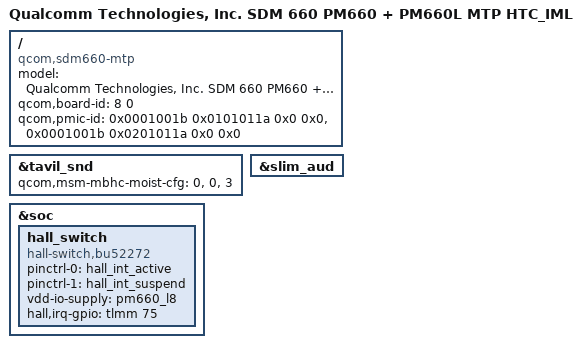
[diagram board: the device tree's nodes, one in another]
/* Copyright (c) 2016-2017, The Linux Foundation. All rights reserved.
 *
 * This program is free software; you can redistribute it and/or modify
 * it under the terms of the GNU General Public License version 2 and
 * only version 2 as published by the Free Software Foundation.
 *
 * This program is distributed in the hope that it will be useful,
 * but WITHOUT ANY WARRANTY; without even the implied warranty of
 * MERCHANTABILITY or FITNESS FOR A PARTICULAR PURPOSE.  See the
 * GNU General Public License for more details.
 */


/dts-v1/;

#include "sdm660-htc_iml.dtsi"
#include "sdm660-mtp-htc_iml.dtsi"
#include "sdm660-external-codec.dtsi"
#include "synaptics-dsx-i2c.dtsi"

/ {
	model = "Qualcomm Technologies, Inc. SDM 660 PM660 + PM660L MTP HTC_IML";
	compatible = "qcom,sdm660-mtp", "qcom,sdm660", "qcom,mtp";
	qcom,board-id = <8 0>;
	qcom,pmic-id = <0x0001001b 0x0101011a 0x0 0x0>,
			<0x0001001b 0x0201011a 0x0 0x0>;
};

&tavil_snd {
	qcom,msm-mbhc-moist-cfg = <0>, <0>, <3>;
};

&slim_aud {
	/delete-node/tasha_codec;
};

&soc {
	/delete-node/sound-9335;
};

&soc {
	hall_switch {

		compatible = "hall-switch,bu52272";
		pinctrl-names = "hall_active","hall_suspend";
		pinctrl-0 = <&hall_int_active>;
		pinctrl-1 = <&hall_int_suspend>;
		vdd-io-supply= <&pm660_l8>;
		interrupt-names = "hall_irq";
		hall,irq-gpio = <&tlmm 75 0x0>;
	};
};
